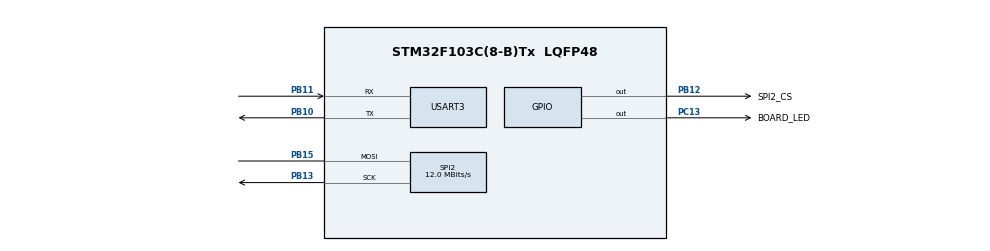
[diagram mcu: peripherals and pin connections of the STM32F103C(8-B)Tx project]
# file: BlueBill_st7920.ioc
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Mcu.Family=STM32F1
Mcu.Name=STM32F103C(8-B)Tx
Mcu.Package=LQFP48
NVIC.PriorityGroup=NVIC_PRIORITYGROUP_4
NVIC.USART3_IRQn=true\:0\:0\:false\:false\:true\:true
PA13.Mode=Serial_Wire
PA13.Signal=SYS_JTMS-SWDIO
PA14.Mode=Serial_Wire
PA14.Signal=SYS_JTCK-SWCLK
PB10.Mode=Asynchronous
PB10.Signal=USART3_TX
PB11.Mode=Asynchronous
PB11.Signal=USART3_RX
PB12.GPIO_Label=SPI2_CS
PB12.Signal=GPIO_Output
PB13.Mode=Simplex_Bidirectional_Master
PB13.Signal=SPI2_SCK
PB15.Mode=Simplex_Bidirectional_Master
PB15.Signal=SPI2_MOSI
PC13-TAMPER-RTC.GPIO_Label=BOARD_LED
PC13-TAMPER-RTC.Signal=GPIO_Output
PC14-OSC32_IN.Mode=LSE-External-Oscillator
PC14-OSC32_IN.Signal=RCC_OSC32_IN
PC15-OSC32_OUT.Mode=LSE-External-Oscillator
PC15-OSC32_OUT.Signal=RCC_OSC32_OUT
PD0-OSC_IN.Mode=HSE-External-Oscillator
PD0-OSC_IN.Signal=RCC_OSC_IN
PD1-OSC_OUT.Mode=HSE-External-Oscillator
PD1-OSC_OUT.Signal=RCC_OSC_OUT
ProjectManager.HeapSize=0x0
ProjectManager.StackSize=0x400
ProjectManager.TargetToolchain=TrueSTUDIO
RCC.AHBFreq_Value=48000000
RCC.APB1CLKDivider=RCC_HCLK_DIV2
RCC.APB1Freq_Value=24000000
RCC.APB1TimFreq_Value=48000000
RCC.APB2Freq_Value=48000000
RCC.APB2TimFreq_Value=48000000
RCC.HCLKFreq_Value=48000000
RCC.PLLMUL=RCC_PLL_MUL6
RCC.PLLSourceVirtual=RCC_PLLSOURCE_HSE
RCC.SYSCLKFreq_VALUE=48000000
RCC.SYSCLKSource=RCC_SYSCLKSOURCE_PLLCLK
RCC.USBFreq_Value=48000000
SPI2.CalculateBaudRate=12.0 MBits/s
SPI2.Direction=SPI_DIRECTION_1LINE
SPI2.Mode=SPI_MODE_MASTER
SPI2.VirtualType=VM_MASTER
USART3.VirtualMode=VM_ASYNC
board=BlueBill_Borad

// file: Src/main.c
/* USER CODE BEGIN Header */
/**
  ******************************************************************************
  * @file           : main.c
  * @brief          : Main program body
  ******************************************************************************
  ** This notice applies to any and all portions of this file
  * that are not between comment pairs USER CODE BEGIN and
  * USER CODE END. Other portions of this file, whether
  * inserted by the user or by software development tools
  * are owned by their respective copyright owners.
  *
  * COPYRIGHT(c) 2019 STMicroelectronics
  *
  * Redistribution and use in source and binary forms, with or without modification,
  * are permitted provided that the following conditions are met:
  *   1. Redistributions of source code must retain the above copyright notice,
  *      this list of conditions and the following disclaimer.
  *   2. Redistributions in binary form must reproduce the above copyright notice,
  *      this list of conditions and the following disclaimer in the documentation
  *      and/or other materials provided with the distribution.
  *   3. Neither the name of STMicroelectronics nor the names of its contributors
  *      may be used to endorse or promote products derived from this software
  *      without specific prior written permission.
  *
  * THIS SOFTWARE IS PROVIDED BY THE COPYRIGHT HOLDERS AND CONTRIBUTORS "AS IS"
  * AND ANY EXPRESS OR IMPLIED WARRANTIES, INCLUDING, BUT NOT LIMITED TO, THE
  * IMPLIED WARRANTIES OF MERCHANTABILITY AND FITNESS FOR A PARTICULAR PURPOSE ARE
  * DISCLAIMED. IN NO EVENT SHALL THE COPYRIGHT HOLDER OR CONTRIBUTORS BE LIABLE
  * FOR ANY DIRECT, INDIRECT, INCIDENTAL, SPECIAL, EXEMPLARY, OR CONSEQUENTIAL
  * DAMAGES (INCLUDING, BUT NOT LIMITED TO, PROCUREMENT OF SUBSTITUTE GOODS OR
  * SERVICES; LOSS OF USE, DATA, OR PROFITS; OR BUSINESS INTERRUPTION) HOWEVER
  * CAUSED AND ON ANY THEORY OF LIABILITY, WHETHER IN CONTRACT, STRICT LIABILITY,
  * OR TORT (INCLUDING NEGLIGENCE OR OTHERWISE) ARISING IN ANY WAY OUT OF THE USE
  * OF THIS SOFTWARE, EVEN IF ADVISED OF THE POSSIBILITY OF SUCH DAMAGE.
  *
  ******************************************************************************
  */
/* USER CODE END Header */

#include "main.h"

/* USER CODE BEGIN Includes */
#include "system.h"
#include "ST7920.h"
#include "u8g2.h"

static u8g2_t u8g2;

/* USER CODE END Includes */

void SystemClock_Config(void);
static void MX_GPIO_Init(void);
static void MX_USART3_UART_Init(void);
static void MX_SPI2_Init(void);

int main(void)
{

  /* MCU Configuration--------------------------------------------------------*/

  /* Reset of all peripherals, Initializes the Flash interface and the Systick. */

  LL_APB2_GRP1_EnableClock(LL_APB2_GRP1_PERIPH_AFIO);
  LL_APB1_GRP1_EnableClock(LL_APB1_GRP1_PERIPH_PWR);

  NVIC_SetPriorityGrouping(NVIC_PRIORITYGROUP_4);

  /* System interrupt init*/

  /**NOJTAG: JTAG-DP Disabled and SW-DP Enabled
  */
  //LL_GPIO_AF_Remap_SWJ_NOJTAG();

  /* USER CODE BEGIN Init */
  LL_USART_Disable(USART3);
  /* USER CODE END Init */

  /* Configure the system clock */
  SystemClock_Config();

  /* Initialize all configured peripherals */
  MX_GPIO_Init();
  MX_USART3_UART_Init();
  MX_SPI2_Init();
  /* USER CODE BEGIN 2 */
  LL_SPI_Enable(SPI2);
  LL_SYSTICK_EnableIT();

  /* u8glib2 will use frame buffer */
  u8g2_Setup_st7920_s_128x64_f(&u8g2, U8G2_R0, u8x8_byte_4wire_sw_spi, u8g2_gpio_and_delay_stm32); /* init u8g2 contetx */
  u8g2_InitDisplay(&u8g2);
  u8g2_SetPowerSave(&u8g2, 0); /* wake up display */

  /* USER CODE END 2 */

  /* Infinite loop */
  while (1)
  {
	  LL_GPIO_TogglePin(BOARD_LED_GPIO_Port, BOARD_LED_Pin);
	  u8g2_ClearBuffer(&u8g2);
	  u8g2_SetFontMode(&u8g2, 1);
	  u8g2_SetFontDirection(&u8g2, 0);
	  u8g2_SetFont(&u8g2, u8g2_font_helvB18_te);

	  u8g2_DrawStr(&u8g2,  0, 24, "hello world");
	  u8g2_DrawStr(&u8g2,  0, 50, "u8g2lib");
	  u8g2_SetFont(&u8g2, u8g2_font_u8glib_4_tf);
	  u8g2_DrawStr(&u8g2,  0, 60, "F.O 2019");
	  u8g2_SendBuffer(&u8g2);

	  delay_ms(1500);

	  u8g2_ClearBuffer(&u8g2);
	  u8g2_SetFontDirection(&u8g2, 0);

	  u8g2_SetFont(&u8g2, u8g2_font_inb24_mf);
	  u8g2_DrawStr(&u8g2, 0, 30, "U");

	  u8g2_SetFontDirection(&u8g2, 1);
	  u8g2_SetFont(&u8g2, u8g2_font_inb30_mn);
	  u8g2_DrawStr(&u8g2, 21,8,"8");

	  u8g2_SetFontDirection(&u8g2, 0);
	  u8g2_SetFont(&u8g2, u8g2_font_inb24_mf);
	  u8g2_DrawStr(&u8g2, 51,30,"g");
	  u8g2_DrawStr(&u8g2, 67,30,"\xb2");

	  u8g2_DrawHLine(&u8g2, 2, 35, 47);
	  u8g2_DrawHLine(&u8g2, 3, 36, 47);
	  u8g2_DrawVLine(&u8g2, 45, 32, 12);
	  u8g2_DrawVLine(&u8g2, 46, 33, 12);
	  u8g2_SendBuffer(&u8g2);

	  LL_GPIO_TogglePin(BOARD_LED_GPIO_Port, BOARD_LED_Pin);
	  delay_ms(1500);

  }
}

void SystemClock_Config(void)
{
  LL_FLASH_SetLatency(LL_FLASH_LATENCY_1);

  if(LL_FLASH_GetLatency() != LL_FLASH_LATENCY_1)
  {
    Error_Handler();
  }
  LL_RCC_HSE_Enable();

   /* Wait till HSE is ready */
  while(LL_RCC_HSE_IsReady() != 1)
  {

  }
  LL_RCC_PLL_ConfigDomain_SYS(LL_RCC_PLLSOURCE_HSE_DIV_1, LL_RCC_PLL_MUL_6);
  LL_RCC_PLL_Enable();

   /* Wait till PLL is ready */
  while(LL_RCC_PLL_IsReady() != 1)
  {

  }
  LL_RCC_SetAHBPrescaler(LL_RCC_SYSCLK_DIV_1);
  LL_RCC_SetAPB1Prescaler(LL_RCC_APB1_DIV_2);
  LL_RCC_SetAPB2Prescaler(LL_RCC_APB2_DIV_1);
  LL_RCC_SetSysClkSource(LL_RCC_SYS_CLKSOURCE_PLL);

   /* Wait till System clock is ready */
  while(LL_RCC_GetSysClkSource() != LL_RCC_SYS_CLKSOURCE_STATUS_PLL)
  {

  }
  LL_Init1msTick(48000000);
  LL_SYSTICK_SetClkSource(LL_SYSTICK_CLKSOURCE_HCLK);
  LL_SetSystemCoreClock(48000000);
}

static void MX_SPI2_Init(void)
{

  LL_SPI_InitTypeDef SPI_InitStruct = {0};

  LL_GPIO_InitTypeDef GPIO_InitStruct = {0};

  /* Peripheral clock enable */
  LL_APB1_GRP1_EnableClock(LL_APB1_GRP1_PERIPH_SPI2);

  LL_APB2_GRP1_EnableClock(LL_APB2_GRP1_PERIPH_GPIOB);
  /**SPI2 GPIO Configuration
  PB13   ------> SPI2_SCK
  PB15   ------> SPI2_MOSI
  */
  GPIO_InitStruct.Pin = LL_GPIO_PIN_13|LL_GPIO_PIN_15;
  GPIO_InitStruct.Mode = LL_GPIO_MODE_ALTERNATE;
  GPIO_InitStruct.Speed = LL_GPIO_SPEED_FREQ_HIGH;
  GPIO_InitStruct.OutputType = LL_GPIO_OUTPUT_PUSHPULL;
  LL_GPIO_Init(GPIOB, &GPIO_InitStruct);

  /* SPI2 parameter configuration*/
  SPI_InitStruct.TransferDirection = LL_SPI_HALF_DUPLEX_TX;
  SPI_InitStruct.Mode = LL_SPI_MODE_MASTER;
  SPI_InitStruct.DataWidth = LL_SPI_DATAWIDTH_8BIT;
  SPI_InitStruct.ClockPolarity = LL_SPI_POLARITY_LOW;
  SPI_InitStruct.ClockPhase = LL_SPI_PHASE_1EDGE;
  SPI_InitStruct.NSS = LL_SPI_NSS_SOFT;
  SPI_InitStruct.BaudRate = LL_SPI_BAUDRATEPRESCALER_DIV2;
  SPI_InitStruct.BitOrder = LL_SPI_MSB_FIRST;
  SPI_InitStruct.CRCCalculation = LL_SPI_CRCCALCULATION_DISABLE;
  SPI_InitStruct.CRCPoly = 10;
  LL_SPI_Init(SPI2, &SPI_InitStruct);

}

static void MX_USART3_UART_Init(void)
{

  LL_USART_InitTypeDef USART_InitStruct = {0};

  LL_GPIO_InitTypeDef GPIO_InitStruct = {0};

  /* Peripheral clock enable */
  LL_APB1_GRP1_EnableClock(LL_APB1_GRP1_PERIPH_USART3);

  LL_APB2_GRP1_EnableClock(LL_APB2_GRP1_PERIPH_GPIOB);
  /**USART3 GPIO Configuration
  PB10   ------> USART3_TX
  PB11   ------> USART3_RX
  */
  GPIO_InitStruct.Pin = LL_GPIO_PIN_10;
  GPIO_InitStruct.Mode = LL_GPIO_MODE_ALTERNATE;
  GPIO_InitStruct.Speed = LL_GPIO_SPEED_FREQ_HIGH;
  GPIO_InitStruct.OutputType = LL_GPIO_OUTPUT_PUSHPULL;
  LL_GPIO_Init(GPIOB, &GPIO_InitStruct);

  GPIO_InitStruct.Pin = LL_GPIO_PIN_11;
  GPIO_InitStruct.Mode = LL_GPIO_MODE_FLOATING;
  LL_GPIO_Init(GPIOB, &GPIO_InitStruct);

  /* USART3 interrupt Init */
  NVIC_SetPriority(USART3_IRQn, NVIC_EncodePriority(NVIC_GetPriorityGrouping(),0, 0));
  NVIC_EnableIRQ(USART3_IRQn);

  USART_InitStruct.BaudRate = 115200;
  USART_InitStruct.DataWidth = LL_USART_DATAWIDTH_8B;
  USART_InitStruct.StopBits = LL_USART_STOPBITS_1;
  USART_InitStruct.Parity = LL_USART_PARITY_NONE;
  USART_InitStruct.TransferDirection = LL_USART_DIRECTION_TX_RX;
  USART_InitStruct.HardwareFlowControl = LL_USART_HWCONTROL_NONE;
  LL_USART_Init(USART3, &USART_InitStruct);
  LL_USART_ConfigAsyncMode(USART3);
  LL_USART_Enable(USART3);

}

static void MX_GPIO_Init(void)
{
  LL_GPIO_InitTypeDef GPIO_InitStruct = {0};

  /* GPIO Ports Clock Enable */
  LL_APB2_GRP1_EnableClock(LL_APB2_GRP1_PERIPH_GPIOC);
  LL_APB2_GRP1_EnableClock(LL_APB2_GRP1_PERIPH_GPIOD);
  LL_APB2_GRP1_EnableClock(LL_APB2_GRP1_PERIPH_GPIOB);
  LL_APB2_GRP1_EnableClock(LL_APB2_GRP1_PERIPH_GPIOA);

  /**/
  LL_GPIO_ResetOutputPin(BOARD_LED_GPIO_Port, BOARD_LED_Pin);

  /**/
  LL_GPIO_ResetOutputPin(SPI2_CS_GPIO_Port, SPI2_CS_Pin);

  /**/
  GPIO_InitStruct.Pin = BOARD_LED_Pin;
  GPIO_InitStruct.Mode = LL_GPIO_MODE_OUTPUT;
  GPIO_InitStruct.Speed = LL_GPIO_SPEED_FREQ_LOW;
  GPIO_InitStruct.OutputType = LL_GPIO_OUTPUT_PUSHPULL;
  LL_GPIO_Init(BOARD_LED_GPIO_Port, &GPIO_InitStruct);

  /**/
  GPIO_InitStruct.Pin = SPI2_CS_Pin;
  GPIO_InitStruct.Mode = LL_GPIO_MODE_OUTPUT;
  GPIO_InitStruct.Speed = LL_GPIO_SPEED_FREQ_LOW;
  GPIO_InitStruct.OutputType = LL_GPIO_OUTPUT_PUSHPULL;
  LL_GPIO_Init(SPI2_CS_GPIO_Port, &GPIO_InitStruct);

}

void Error_Handler(void)
{
}

/************************ (C) COPYRIGHT STMicroelectronics *****END OF FILE****/
